# R7FA4E10D register map
Vendor: Renesas Electronics Corporation; Series: RA4E1; File version: 1.20.00
CPU: CM33 r0p4, little endian, MPU, FPU, VTOR, 4 interrupt priority bits, 96 interrupts
Registers are 8-bit, read-write, reset 0x0 unless marked. A register's access mark holds for its fields unless they carry their own. Offsets are from the block's base; [hi:lo] are bit positions; {n}, {i} and the like mark numbered series.

## QSPI — Quad Serial Peripheral Interface
Base 0x64000000
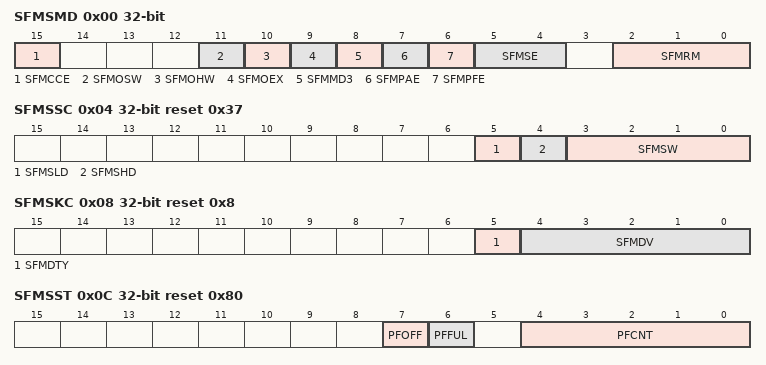
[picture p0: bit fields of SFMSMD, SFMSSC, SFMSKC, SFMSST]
0x00 SFMSMD 32-bit — Transfer Mode Control Register
  [15] SFMCCE — Read instruction code select
    0=Uses automatically generated SPI instruction code; 1=Use instruction code in the SFMSIC register
  [11] SFMOSW — Setup time adjustment for serial transmission
    0=Do not extend low-level width of QSPCLK during transmission; 1=Extend low-level width of QSPCLK by 1 PCLKA during transmission
  [10] SFMOHW — Hold time adjustment for serial transmission
    0=Do not extend high-level width of QSPCLK during transmission; 1=Extend high-level width of QSPCLK by 1 PCLKA during transmission
  [9] SFMOEX — Extension select for the I/O buffer output enable signal for the serial interface
    0=Do not extend; 1=Extend by 1 QSPCLK
  [8] SFMMD3 — SPI mode select.
    0=SPI mode 0; 1=SPI mode 3
  [7] SFMPAE — Function select for stopping prefetch at locations other than on byte boundaries
    0=Disable function; 1=Enable function
  [6] SFMPFE — Prefetch function select
    0=Disable function; 1=Enable function
  [5:4] SFMSE — QSSL extension function select after SPI bus access
    0=Do not extend QSSL; 1=Extend QSSL by 33 QSPCLK; 2=Extend QSSL by 129 QSPCLK; 3=Extend QSSL infinitely
  [2:0] SFMRM — Serial interface read mode select
    0=Standard Read; 1=Fast Read; 2=Fast Read Dual Output; 3=Fast Read Dual I/O; 4=Fast Read Quad Output; 5=Fast Read Quad I/O; other=Others (Setting prohibited)
0x04 SFMSSC 32-bit reset 0x37 — Chip Selection Control Register
  [5] SFMSLD — QSSL Signal Setup Time
    0=QSSL outputs low before 0.5 QSPCLK cycles from the first rising edge of QSPCLK; 1=QSSL outputs low before 1.5 QSPCLK cycles from the first rising edge of QSPCLK
  [4] SFMSHD — QSSL Signal Hold Time
    0=QSSL outputs high after 0.5 QSPCLK cycles from the last rising edge of QSPCLK; 1=QSSL outputs high after 1.5 QSPCLK cycles from the last rising edge of QSPCLK
  [3:0] SFMSW — Minimum High-level Width Select for QSSL Signal
    {v}={v+1} QSPCLK (v=0..15)
0x08 SFMSKC 32-bit reset 0x8 — Clock Control Register
  [5] SFMDTY — Duty ratio correction function select for the QSPCLK signal when divided by an odd number
    0=Make no correction; 1=Make correction
  [4:0] SFMDV — Serial interface reference cycle select. (Pay attention to irregularities.)
    0=2 PCLKA; 1=3 PCLKA (divided by an odd number); 2=4 PCLKA; 3=5 PCLKA (divided by an odd number); 4=6 PCLKA; 5=7 PCLKA (divided by an odd number); 6=8 PCLKA; 7=9 PCLKA (divided by an odd number); 8=10 PCLKA; 9=11 PCLKA (divided by an odd number); 10=12 PCLKA; 11=13 PCLKA (divided by an odd number); 12=14 PCLKA; 13=15 PCLKA (divided by an odd number); 14=16 PCLKA; 15=17 PCLKA (divided by an odd number); 16=18 PCLKA; 17=20 PCLKA; 18=22 PCLKA; 19=24 PCLKA; 20=26 PCLKA; 21=28 PCLKA; 22=30 PCLKA; 23=32 PCLKA; 24=34 PCLKA; 25=36 PCLKA; 26=38 PCLKA; 27=40 PCLKA; 28=42 PCLKA; 29=44 PCLKA; 30=46 PCLKA; 31=48 PCLKA
0x0C SFMSST 32-bit ro reset 0x80 — Status Register
  [7] PFOFF — Prefetch function operating state
    0=Prefetch function operating; 1=Prefetch function not enabled or not operating
  [6] PFFUL — Prefetch buffer state
    0=Prefetch buffer has free space; 1=Prefetch buffer is full
  [4:0] PFCNT — Number of bytes of prefetched data
    0=0 byte; 1=1 byte; {v}={v} bytes (v=2..18); other=Others (Reserved)
0x10 SFMCOM 32-bit (reset mask 0xFFFFFF00) — Communication Port Register
  [7:0] SFMD — Port for direct communication with the SPI bus
0x14 SFMCMD 32-bit — Communication Mode Control Register
  [0] DCOM — Mode select for communication with the SPI bus
    0=ROM access mode; 1=Direct communication mode
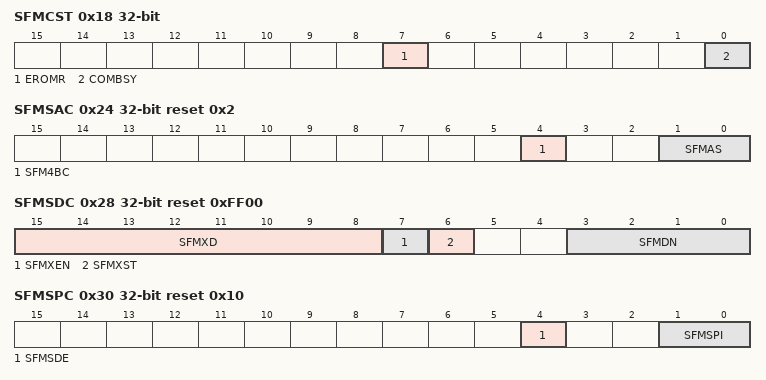
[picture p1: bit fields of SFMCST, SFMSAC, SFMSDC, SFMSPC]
0x18 SFMCST 32-bit — Communication Status Register
  [7] EROMR — ROM access detection status in direct communication mode
    0=ROM access not detected; 1=ROM access detected
  [0] COMBSY ro — SPI bus cycle completion state in direct communication
    0=No serial transfer being processed; 1=Serial transfer being processed
0x20 SFMSIC 32-bit — Instruction Code Register
  [7:0] SFMCIC — Serial flash instruction code to substitute
0x24 SFMSAC 32-bit reset 0x2 — Address Mode Control Register
  [4] SFM4BC — Selection of instruction code automatically generated when the serial interface address width is 4 bytes
    0=Do not use 4-byte address read instruction code; 1=Use 4-byte address read instruction code
  [1:0] SFMAS — Number of address bytes select for the serial interface
    0=1 byte; 1=2 bytes; 2=3 bytes; 3=4 bytes
0x28 SFMSDC 32-bit reset 0xFF00 — Dummy Cycle Control Register
  [15:8] SFMXD — Mode data for serial flash (Controls XIP mode.)
  [7] SFMXEN — XIP mode permission
    0=Prohibit XIP mode; 1=Permit XIP mode
  [6] SFMXST ro — XIP mode status
    0=Normal (non-XIP) mode; 1=XIP mode
  [3:0] SFMDN — Number of dummy cycles select for Fast Read instructions
    0=Default dummy cycles for each instruction: - Fast Read Quad I/O: 6 QSPCLK - Fast Read Quad Output: 8 QSPCLK - Fast Read Dual I/O: 4 QSPCLK - Fast Read Dual Output: 8 QSPCLK - Fast Read: 8 QSPCLK; {v}={v+2} QSPCLK (v=1..15)
0x30 SFMSPC 32-bit reset 0x10 — SPI Protocol Control Register
  [4] SFMSDE — QSPCLK extended selection bit when switching I/O of QIOn pin
    0=No QSPCLK extension; 1=QSPCLK expansion when switching I/O direction of QIOn pin
  [1:0] SFMSPI — SPI protocol select
    0=Single SPI Protocol, Extended SPI protocol; 1=Dual SPI protocol; 2=Quad SPI protocol; 3=Setting prohibited
0x34 SFMPMD 32-bit — Port Control Register
  [2] SFMWPL — WP pin level specification
    0=Low level; 1=High level
0x804 SFMCNT1 32-bit — External QSPI Address Register
  [31:26] QSPI_EXT — Bank switching address
